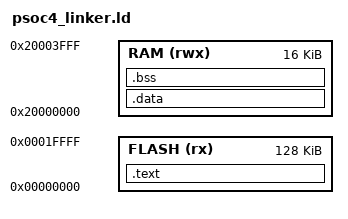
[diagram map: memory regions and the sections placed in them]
/* Linker script for PSoC 4100S Plus 256KB */
MEMORY
{
    FLASH (rx)  : ORIGIN = 0x00000000, LENGTH = 128K
    RAM   (rwx) : ORIGIN = 0x20000000, LENGTH = 16K
}

ENTRY(Reset_Handler)

SECTIONS
{
    .text :
    {
        KEEP(*(.isr_vector))
        *(.text*)
        *(.rodata*)
        . = ALIGN(4);
        _etext = .;
    } > FLASH

    .data : AT(_etext)
    {
        _sdata = .;
        *(.data*)
        . = ALIGN(4);
        _edata = .;
    } > RAM

    .bss :
    {
        _sbss = .;
        *(.bss*)
        *(COMMON)
        . = ALIGN(4);
        _ebss = .;
    } > RAM

    end = .;
    _end = end;
    __end__ = end;

    /* Stack at the end of RAM */
    _estack = ORIGIN(RAM) + LENGTH(RAM);
}
